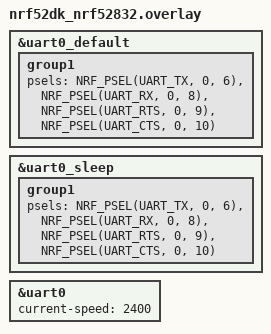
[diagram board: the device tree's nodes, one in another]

/* Overlay to disable UART0 hardware flow control */
// &uart0 {
//     current-speed = <115200>;  /* Set baud rate */
//     tx-pin = <6>;              /* TXD pin: P0.06 */
//     rx-pin = <8>;              /* RXD pin: P0.08 */
//     rts-pin = <0xFFFFFFFF>;            /* Disable RTS */
//     cts-pin = <0xFFFFFFFF>;            /* Disable CTS */
//     flow-control = "none";     /* Disable HW flow control */
//     status = "okay";           /* Ensure the device is enabled */
// };

// uart0: arduino_serial: uart@40002000 {
// 	compatible = "nordic,nrf-uarte";
// 	reg = <0x40002000 0x1000>;
// 	interrupts = <2 NRF_DEFAULT_IRQ_PRIORITY>;
// 	status = "okay";
// 	current-speed = <115200>;
// 	pinctrl-0 = <&uart0_default>;
// 	pinctrl-1 = <&uart0_sleep>;
// 	pinctrl-names = "default", "sleep";
// 	tx-pin = <6>;
// 	rx-pin = <8>;
// 	rts-pin = <0xFFFFFFFF>;
// 	cts-pin = <0xFFFFFFFF>;
// 	flow-control = "none";
// };

// /* Overlay to disable UART0 hardware flow control */
// &uart0 {
//     compatible = "nordic,nrf-uarte"; /* Use the correct compatible for the UART */
//     current-speed = <115200>;       /* Set the baud rate */
//     status = "okay";                /* Ensure UART is enabled */
//     flow-control = "none";          /* Disable hardware flow control */
//     pinctrl-0 = <&uart0_default>;   /* Use default pin configuration */
//     pinctrl-names = "default";      /* Define the pinctrl name */
// };
&uart0_default {
	group1 {
		psels = <NRF_PSEL(UART_TX, 0, 6)>,
				<NRF_PSEL(UART_RX, 0, 8)>,
				<NRF_PSEL(UART_RTS, 0, 9)>,
				<NRF_PSEL(UART_CTS, 0, 10)>;
	};
};

&uart0_sleep {
	group1 {
		psels = <NRF_PSEL(UART_TX, 0, 6)>,
				<NRF_PSEL(UART_RX, 0, 8)>,
				<NRF_PSEL(UART_RTS, 0, 9)>,
				<NRF_PSEL(UART_CTS, 0, 10)>;
	};
};

&uart0 {
	current-speed = <2400>;
};
